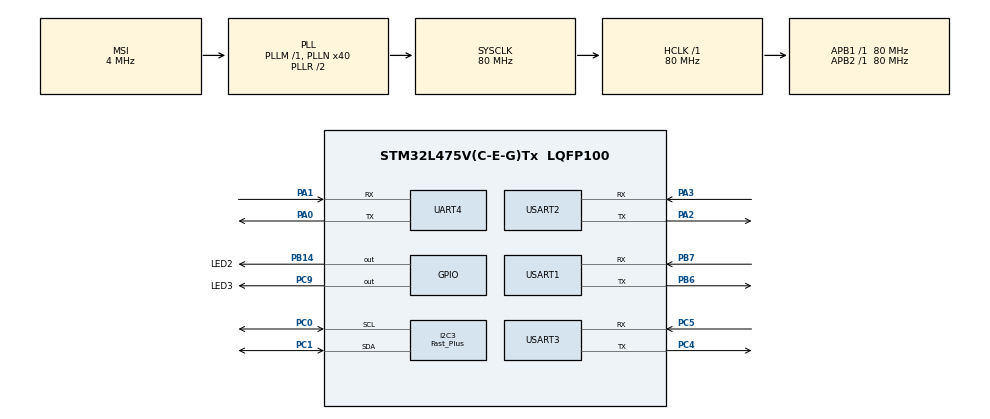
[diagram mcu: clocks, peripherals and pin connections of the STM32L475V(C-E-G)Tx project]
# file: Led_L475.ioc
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Dma.I2C3_TX.0.Direction=DMA_MEMORY_TO_PERIPH
Dma.I2C3_TX.0.Instance=DMA1_Channel2
Dma.I2C3_TX.0.MemDataAlignment=DMA_MDATAALIGN_BYTE
Dma.I2C3_TX.0.MemInc=DMA_MINC_ENABLE
Dma.I2C3_TX.0.Mode=DMA_NORMAL
Dma.I2C3_TX.0.PeriphDataAlignment=DMA_PDATAALIGN_BYTE
Dma.I2C3_TX.0.PeriphInc=DMA_PINC_DISABLE
Dma.I2C3_TX.0.Priority=DMA_PRIORITY_LOW
Dma.Request0=I2C3_TX
FREERTOS.Tasks01=defaultTask,24,128,StartDefaultTask,Default,NULL,Dynamic,NULL,NULL
FREERTOS.Timers01=OledTimer,OledCallback,osTimerPeriodic,Default,NULL,Dynamic,NULL;msTimer,msTimerCallback,osTimerPeriodic,Default,NULL,Dynamic,NULL
FREERTOS.configENABLE_FPU=1
I2C3.I2C_Speed_Mode=I2C_Fast_Plus
I2C3.Timing=0x00B10E24
Mcu.Family=STM32L4
Mcu.Name=STM32L475V(C-E-G)Tx
Mcu.Package=LQFP100
NVIC.DMA1_Channel2_IRQn=true\:5\:0\:false\:false\:true\:true\:false\:true\:true
NVIC.I2C3_EV_IRQn=true\:5\:0\:false\:false\:true\:true\:true\:true\:true
NVIC.PriorityGroup=NVIC_PRIORITYGROUP_4
NVIC.TIM6_DAC_IRQn=true\:15\:0\:false\:false\:true\:false\:false\:true\:true
NVIC.TimeBase=TIM6_DAC_IRQn
NVIC.TimeBaseIP=TIM6
PA0.Mode=Asynchronous
PA0.Signal=UART4_TX
PA1.Mode=Asynchronous
PA1.Signal=UART4_RX
PA13\ (JTMS-SWDIO).Mode=Serial_Wire
PA13\ (JTMS-SWDIO).Signal=SYS_JTMS-SWDIO
PA14\ (JTCK-SWCLK).Mode=Serial_Wire
PA14\ (JTCK-SWCLK).Signal=SYS_JTCK-SWCLK
PA2.Mode=Asynchronous
PA2.Signal=USART2_TX
PA3.Mode=Asynchronous
PA3.Signal=USART2_RX
PB14.GPIO_Label=LED2
PB14.PinState=GPIO_PIN_SET
PB14.Signal=GPIO_Output
PB6.Mode=Asynchronous
PB6.Signal=USART1_TX
PB7.Mode=Asynchronous
PB7.Signal=USART1_RX
PC0.Mode=I2C
PC0.Signal=I2C3_SCL
PC1.Mode=I2C
PC1.Signal=I2C3_SDA
PC14-OSC32_IN\ (PC14).Mode=LSE-External-Oscillator
PC14-OSC32_IN\ (PC14).Signal=RCC_OSC32_IN
PC15-OSC32_OUT\ (PC15).Mode=LSE-External-Oscillator
PC15-OSC32_OUT\ (PC15).Signal=RCC_OSC32_OUT
PC4.Mode=Asynchronous
PC4.Signal=USART3_TX
PC5.Mode=Asynchronous
PC5.Signal=USART3_RX
PC9.GPIO_Label=LED3
PC9.Signal=GPIO_Output
ProjectManager.HeapSize=0x200
ProjectManager.StackSize=0x400
ProjectManager.TargetToolchain=STM32CubeIDE
RCC.ADCFreq_Value=16000000
RCC.AHBFreq_Value=80000000
RCC.APB1Freq_Value=80000000
RCC.APB1TimFreq_Value=80000000
RCC.APB2Freq_Value=80000000
RCC.APB2TimFreq_Value=80000000
RCC.CortexFreq_Value=80000000
RCC.HCLKFreq_Value=80000000
RCC.HSE_VALUE=8000000
RCC.HSI_VALUE=16000000
RCC.LSE_Drive_CapabilityArg=+LSE_Drive_Capability
RCC.MSIAutoCalibration=ENABLED
RCC.MSI_VALUE=4000000
RCC.PLLN=40
RCC.SYSCLKFreq_VALUE=80000000
RCC.SYSCLKSource=RCC_SYSCLKSOURCE_PLLCLK
RCC.USBFreq_Value=16000000
RCC.VCOOutputFreq_Value=160000000
USART1.VirtualMode-Asynchronous=VM_ASYNC
USART2.VirtualMode-Asynchronous=VM_ASYNC
USART3.VirtualMode-Asynchronous=VM_ASYNC
VP_FREERTOS_VS_CMSIS_V2.Mode=CMSIS_V2
VP_SYS_VS_tim6.Mode=TIM6
board=custom

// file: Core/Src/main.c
/* USER CODE BEGIN Header */
/**
  ******************************************************************************
  * @file           : main.c
  * @brief          : Main program body
  ******************************************************************************
  * @attention
  *
  * Copyright (c) 2026 STMicroelectronics.
  * All rights reserved.
  *
  * This software is licensed under terms that can be found in the LICENSE file
  * in the root directory of this software component.
  * If no LICENSE file comes with this software, it is provided AS-IS.
  *
  ******************************************************************************
  */
/* USER CODE END Header */
#include "main.h"
#include "cmsis_os.h"
#include "dma.h"
#include "i2c.h"
#include "usart.h"
#include "gpio.h"

void SystemClock_Config(void);
void MX_FREERTOS_Init(void);

int main(void)
{

  /* MCU Configuration--------------------------------------------------------*/

  /* Reset of all peripherals, Initializes the Flash interface and the Systick. */
  HAL_Init();

  /* Configure the system clock */
  SystemClock_Config();

  /* Initialize all configured peripherals */
  MX_GPIO_Init();
  MX_DMA_Init();
  MX_I2C3_Init();
  MX_UART4_Init();
  MX_USART1_UART_Init();
  MX_USART2_UART_Init();
  MX_USART3_UART_Init();

  /* Init scheduler */
  osKernelInitialize();  /* Call init function for freertos objects (in cmsis_os2.c) */
  MX_FREERTOS_Init();

  /* Start scheduler */
  osKernelStart();

  /* We should never get here as control is now taken by the scheduler */

  /* Infinite loop */
  while (1)
  {

  }
}

void SystemClock_Config(void)
{
  RCC_OscInitTypeDef RCC_OscInitStruct = {0};
  RCC_ClkInitTypeDef RCC_ClkInitStruct = {0};

  /** Configure the main internal regulator output voltage
  */
  if (HAL_PWREx_ControlVoltageScaling(PWR_REGULATOR_VOLTAGE_SCALE1) != HAL_OK)
  {
    Error_Handler();
  }

  /** Configure LSE Drive Capability
  */
  HAL_PWR_EnableBkUpAccess();
  __HAL_RCC_LSEDRIVE_CONFIG(RCC_LSEDRIVE_LOW);

  /** Initializes the RCC Oscillators according to the specified parameters
  * in the RCC_OscInitTypeDef structure.
  */
  RCC_OscInitStruct.OscillatorType = RCC_OSCILLATORTYPE_LSE|RCC_OSCILLATORTYPE_MSI;
  RCC_OscInitStruct.LSEState = RCC_LSE_ON;
  RCC_OscInitStruct.MSIState = RCC_MSI_ON;
  RCC_OscInitStruct.MSICalibrationValue = 0;
  RCC_OscInitStruct.MSIClockRange = RCC_MSIRANGE_6;
  RCC_OscInitStruct.PLL.PLLState = RCC_PLL_ON;
  RCC_OscInitStruct.PLL.PLLSource = RCC_PLLSOURCE_MSI;
  RCC_OscInitStruct.PLL.PLLM = 1;
  RCC_OscInitStruct.PLL.PLLN = 40;
  RCC_OscInitStruct.PLL.PLLP = RCC_PLLP_DIV7;
  RCC_OscInitStruct.PLL.PLLQ = RCC_PLLQ_DIV2;
  RCC_OscInitStruct.PLL.PLLR = RCC_PLLR_DIV2;
  if (HAL_RCC_OscConfig(&RCC_OscInitStruct) != HAL_OK)
  {
    Error_Handler();
  }

  /** Initializes the CPU, AHB and APB buses clocks
  */
  RCC_ClkInitStruct.ClockType = RCC_CLOCKTYPE_HCLK|RCC_CLOCKTYPE_SYSCLK
                              |RCC_CLOCKTYPE_PCLK1|RCC_CLOCKTYPE_PCLK2;
  RCC_ClkInitStruct.SYSCLKSource = RCC_SYSCLKSOURCE_PLLCLK;
  RCC_ClkInitStruct.AHBCLKDivider = RCC_SYSCLK_DIV1;
  RCC_ClkInitStruct.APB1CLKDivider = RCC_HCLK_DIV1;
  RCC_ClkInitStruct.APB2CLKDivider = RCC_HCLK_DIV1;

  if (HAL_RCC_ClockConfig(&RCC_ClkInitStruct, FLASH_LATENCY_4) != HAL_OK)
  {
    Error_Handler();
  }

  /** Enable MSI Auto calibration
  */
  HAL_RCCEx_EnableMSIPLLMode();
}

void HAL_TIM_PeriodElapsedCallback(TIM_HandleTypeDef *htim)
{
  if (htim->Instance == TIM6)
  {
    HAL_IncTick();
  }
}

void Error_Handler(void)
{
  __disable_irq();
  while (1)
  {
  }
}

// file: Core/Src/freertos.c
/* USER CODE BEGIN Header */
/**
  ******************************************************************************
  * File Name          : freertos.c
  * Description        : Code for freertos applications
  ******************************************************************************
  * @attention
  *
  * Copyright (c) 2026 STMicroelectronics.
  * All rights reserved.
  *
  * This software is licensed under terms that can be found in the LICENSE file
  * in the root directory of this software component.
  * If no LICENSE file comes with this software, it is provided AS-IS.
  *
  ******************************************************************************
  */
/* USER CODE END Header */

#include "FreeRTOS.h"
#include "task.h"
#include "main.h"
#include "cmsis_os.h"

/* Definitions for defaultTask */
osThreadId_t defaultTaskHandle;
const osThreadAttr_t defaultTask_attributes = {
  .name = "defaultTask",
  .stack_size = 128 * 4,
  .priority = (osPriority_t) osPriorityNormal,
};
/* Definitions for OledTimer */
osTimerId_t OledTimerHandle;
const osTimerAttr_t OledTimer_attributes = {
  .name = "OledTimer"
};
/* Definitions for msTimer */
osTimerId_t msTimerHandle;
const osTimerAttr_t msTimer_attributes = {
  .name = "msTimer"
};

void StartDefaultTask(void *argument);
void OledCallback(void *argument);
void msTimerCallback(void *argument);

void MX_FREERTOS_Init(void); /* (MISRA C 2004 rule 8.1) */

void MX_FREERTOS_Init(void) {

  /* Create the timer(s) */
  /* creation of OledTimer */
  OledTimerHandle = osTimerNew(OledCallback, osTimerPeriodic, NULL, &OledTimer_attributes);

  /* creation of msTimer */
  msTimerHandle = osTimerNew(msTimerCallback, osTimerPeriodic, NULL, &msTimer_attributes);

  /* USER CODE BEGIN RTOS_TIMERS */
  /* start timers, add new ones, ... */
  osTimerStart(OledTimerHandle,500);
  osTimerStart(msTimerHandle,50);
  /* USER CODE END RTOS_TIMERS */

  /* Create the thread(s) */
  /* creation of defaultTask */
  defaultTaskHandle = osThreadNew(StartDefaultTask, NULL, &defaultTask_attributes);

}

void StartDefaultTask(void *argument)
{
  for(;;)
  {
    osDelay(1);
  }
}

/* OledCallback function */
void OledCallback(void *argument)
{
  /* USER CODE BEGIN OledCallback */
  HAL_GPIO_TogglePin(LED2_GPIO_Port,LED2_Pin);

  /* USER CODE END OledCallback */
}

/* msTimerCallback function */
void msTimerCallback(void *argument)
{
  /* USER CODE BEGIN msTimerCallback */
  HAL_GPIO_TogglePin(LED3_GPIO_Port,LED3_Pin);
  /* USER CODE END msTimerCallback */
}
